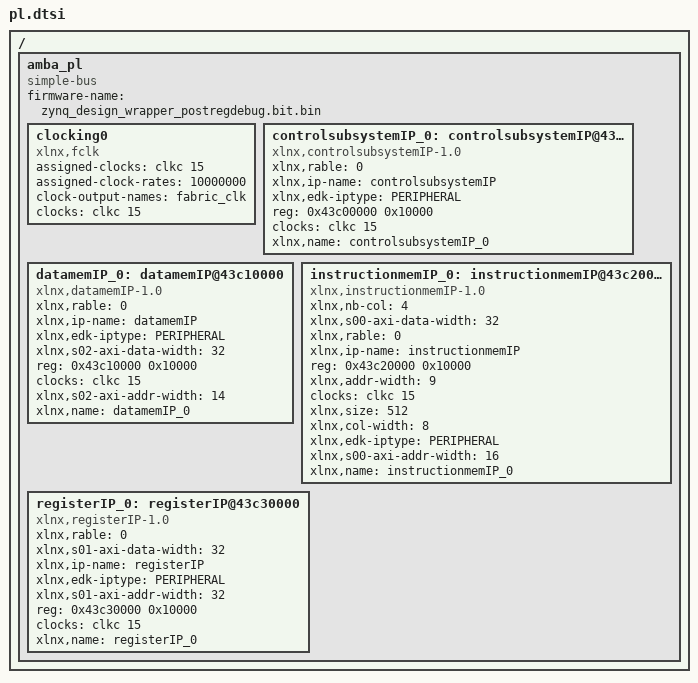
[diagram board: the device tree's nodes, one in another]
/ {
	amba_pl: amba_pl {
		ranges;
		compatible = "simple-bus";
		#address-cells = <1>;
		#size-cells = <1>;
		firmware-name = "zynq_design_wrapper_postregdebug.bit.bin";
		clocking0: clocking0 {
			compatible = "xlnx,fclk";
			assigned-clocks = <&clkc 15>;
			assigned-clock-rates = <10000000>;
			#clock-cells = <0>;
			clock-output-names = "fabric_clk";
			clocks = <&clkc 15>;
		};
		controlsubsystemIP_0: controlsubsystemIP@43c00000 {
			xlnx,rable = <0>;
			compatible = "xlnx,controlsubsystemIP-1.0";
			status = "okay";
			clock-names = "s05_axi_aclk";
			xlnx,ip-name = "controlsubsystemIP";
			xlnx,edk-iptype = "PERIPHERAL";
			reg = <0x43c00000 0x10000>;
			clocks = <&clkc 15>;
			xlnx,name = "controlsubsystemIP_0";
		};
		datamemIP_0: datamemIP@43c10000 {
			xlnx,rable = <0>;
			compatible = "xlnx,datamemIP-1.0";
			status = "okay";
			clock-names = "s02_axi_aclk";
			xlnx,ip-name = "datamemIP";
			xlnx,edk-iptype = "PERIPHERAL";
			xlnx,s02-axi-data-width = <32>;
			reg = <0x43c10000 0x10000>;
			clocks = <&clkc 15>;
			xlnx,s02-axi-addr-width = <14>;
			xlnx,name = "datamemIP_0";
		};
		instructionmemIP_0: instructionmemIP@43c20000 {
			compatible = "xlnx,instructionmemIP-1.0";
			xlnx,nb-col = <4>;
			xlnx,s00-axi-data-width = <32>;
			xlnx,rable = <0>;
			xlnx,ip-name = "instructionmemIP";
			reg = <0x43c20000 0x10000>;
			xlnx,addr-width = <9>;
			clocks = <&clkc 15>;
			xlnx,size = <512>;
			xlnx,col-width = <8>;
			xlnx,edk-iptype = "PERIPHERAL";
			status = "okay";
			clock-names = "s00_axi_aclk";
			xlnx,s00-axi-addr-width = <16>;
			xlnx,name = "instructionmemIP_0";
		};
		registerIP_0: registerIP@43c30000 {
			xlnx,rable = <0>;
			compatible = "xlnx,registerIP-1.0";
			status = "okay";
			clock-names = "s01_axi_aclk";
			xlnx,s01-axi-data-width = <32>;
			xlnx,ip-name = "registerIP";
			xlnx,edk-iptype = "PERIPHERAL";
			xlnx,s01-axi-addr-width = <32>;
			reg = <0x43c30000 0x10000>;
			clocks = <&clkc 15>;
			xlnx,name = "registerIP_0";
		};
	};
};
